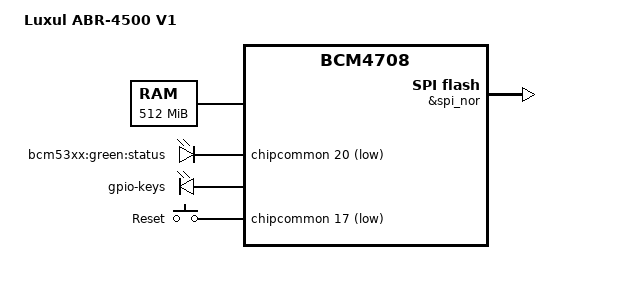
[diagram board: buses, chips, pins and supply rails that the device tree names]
/* bench 10860.0.0 b00227e886ad */
/* bench 10860.0.1 c36ea16845e7 */
/* bench 10860.0.2 73e902c5a733 */
/* bench 10860.0.3 02c1d40f2866 */
/* bench 10860.0.4 607f308c01bf */
/* bench 10860.0.5 0bc4ec869510 */
/* bench 10860.0.6 a900f578a777 */
/* bench 10860.0.7 12f674923b94 */
/* bench 10860.0.8 46af99114848 */
/* bench 10860.0.9 03753964356f */
// SPDX-License-Identifier: GPL-2.0-or-later OR MIT
/*
 * Copyright (C) 2017 Luxul Inc.
 */

/dts-v1/;

#include "bcm4708.dtsi"
#include "bcm5301x-nand-cs0-bch8.dtsi"

/ {
	compatible = "luxul,abr-4500-v1", "brcm,bcm47094", "brcm,bcm4708";
	model = "Luxul ABR-4500 V1";

	chosen {
		bootargs = "earlycon";
	};

	memory@0 {
		device_type = "memory";
		reg = <0x00000000 0x08000000
		       0x88000000 0x18000000>;
	};

	leds {
		compatible = "gpio-leds";

		status {
			label = "bcm53xx:green:status";
			gpios = <&chipcommon 20 GPIO_ACTIVE_LOW>;
/* bench 5441.0.0 0fa7e51345ae */
/* bench 5441.0.1 44190f2a8375 */
/* bench 5441.0.2 557f4e3d03f5 */
/* bench 5441.0.3 e1083e0e08b8 */
/* bench 5441.0.4 6be624e55dc3 */
/* bench 5441.0.5 861d3abe67c9 */
/* bench 5441.0.6 24a4bf6c3acd */
/* bench 5441.0.7 7c7e4639c6a3 */
/* bench 5441.0.8 14ae2bab1b90 */

		usb3 {
			label = "bcm53xx:green:usb3";
			gpios = <&chipcommon 19 GPIO_ACTIVE_LOW>;
			trigger-sources = <&ohci_port1>, <&ehci_port1>,
				<&xhci_port1>;
			linux,default-trigger = "usbport";
		};

	};

	gpio-keys {
		compatible = "gpio-keys";

		restart {
			label = "Reset";
			linux,code = <KEY_RESTART>;
			gpios = <&chipcommon 17 GPIO_ACTIVE_LOW>;
		};
	};
};

&usb3 {
	vcc-gpio = <&chipcommon 18 GPIO_ACTIVE_HIGH>;
};

&spi_nor {
	status = "okay";
};

&usb3_phy {
	status = "okay";
};
